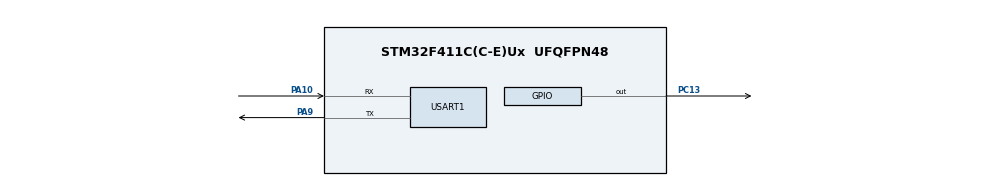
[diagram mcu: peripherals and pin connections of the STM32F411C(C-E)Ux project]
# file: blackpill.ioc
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Dma.Request0=USART1_RX
Dma.Request1=USART1_TX
Dma.USART1_RX.0.Direction=DMA_PERIPH_TO_MEMORY
Dma.USART1_RX.0.FIFOMode=DMA_FIFOMODE_DISABLE
Dma.USART1_RX.0.Instance=DMA2_Stream2
Dma.USART1_RX.0.MemDataAlignment=DMA_MDATAALIGN_BYTE
Dma.USART1_RX.0.MemInc=DMA_MINC_ENABLE
Dma.USART1_RX.0.Mode=DMA_NORMAL
Dma.USART1_RX.0.PeriphDataAlignment=DMA_PDATAALIGN_BYTE
Dma.USART1_RX.0.PeriphInc=DMA_PINC_DISABLE
Dma.USART1_RX.0.Priority=DMA_PRIORITY_LOW
Dma.USART1_TX.1.Direction=DMA_MEMORY_TO_PERIPH
Dma.USART1_TX.1.FIFOMode=DMA_FIFOMODE_DISABLE
Dma.USART1_TX.1.Instance=DMA2_Stream7
Dma.USART1_TX.1.MemDataAlignment=DMA_MDATAALIGN_BYTE
Dma.USART1_TX.1.MemInc=DMA_MINC_ENABLE
Dma.USART1_TX.1.Mode=DMA_NORMAL
Dma.USART1_TX.1.PeriphDataAlignment=DMA_PDATAALIGN_BYTE
Dma.USART1_TX.1.PeriphInc=DMA_PINC_DISABLE
Dma.USART1_TX.1.Priority=DMA_PRIORITY_LOW
Mcu.Family=STM32F4
Mcu.Name=STM32F411C(C-E)Ux
Mcu.Package=UFQFPN48
NVIC.DMA2_Stream2_IRQn=true\:0\:0\:false\:false\:false\:false\:false\:true
NVIC.PriorityGroup=NVIC_PRIORITYGROUP_4
NVIC.USART1_IRQn=true\:0\:0\:false\:false\:false\:true\:false\:true
PA10.Mode=Asynchronous
PA10.Signal=USART1_RX
PA13.Mode=Serial_Wire
PA13.Signal=SYS_JTMS-SWDIO
PA14.Mode=Serial_Wire
PA14.Signal=SYS_JTCK-SWCLK
PA9.Mode=Asynchronous
PA9.Signal=USART1_TX
PC13-ANTI_TAMP.PinState=GPIO_PIN_SET
PC13-ANTI_TAMP.Signal=GPIO_Output
PH0\ -\ OSC_IN.Mode=HSE-External-Oscillator
PH0\ -\ OSC_IN.Signal=RCC_OSC_IN
PH1\ -\ OSC_OUT.Mode=HSE-External-Oscillator
PH1\ -\ OSC_OUT.Signal=RCC_OSC_OUT
ProjectManager.HeapSize=0x200
ProjectManager.StackSize=0x400
ProjectManager.TargetToolchain=Makefile
RCC.48MHZClocksFreq_Value=50000000
RCC.AHBFreq_Value=100000000
RCC.APB1CLKDivider=RCC_HCLK_DIV2
RCC.APB1Freq_Value=50000000
RCC.APB1TimFreq_Value=100000000
RCC.APB2Freq_Value=100000000
RCC.APB2TimFreq_Value=100000000
RCC.CortexFreq_Value=100000000
RCC.HCLKFreq_Value=100000000
RCC.HSE_VALUE=25000000
RCC.HSI_VALUE=16000000
RCC.LSE_VALUE=32768
RCC.PLLM=12
RCC.PLLN=96
RCC.PLLSourceVirtual=RCC_PLLSOURCE_HSE
RCC.SYSCLKFreq_VALUE=100000000
RCC.SYSCLKSource=RCC_SYSCLKSOURCE_PLLCLK
RCC.VCOOutputFreq_Value=200000000
USART1.VirtualMode=VM_ASYNC
board=custom

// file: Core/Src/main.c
/* USER CODE BEGIN Header */
/**
  ******************************************************************************
  * @file           : main.c
  * @brief          : Main program body
  ******************************************************************************
  * @attention
  *
  * Copyright (c) 2025 STMicroelectronics.
  * All rights reserved.
  *
  * This software is licensed under terms that can be found in the LICENSE file
  * in the root directory of this software component.
  * If no LICENSE file comes with this software, it is provided AS-IS.
  *
  ******************************************************************************
  */
/* USER CODE END Header */
#include "main.h"

void SystemClock_Config(void);
static void MX_GPIO_Init(void);
static void MX_DMA_Init(void);
static void MX_USART1_UART_Init(void);

/* USER CODE BEGIN 0 */
void hal_failed_assert_handler(const char* file, const uint32_t line, const uint32_t pc);
void hal_error_handler(const uint32_t pc);
void controller_initialize_hardware_and_start_scheduler(void);
/* USER CODE END 0 */

int main(void)
{

  /* MCU Configuration--------------------------------------------------------*/

  /* Reset of all peripherals, Initializes the Flash interface and the Systick. */
  LL_APB2_GRP1_EnableClock(LL_APB2_GRP1_PERIPH_SYSCFG);
  LL_APB1_GRP1_EnableClock(LL_APB1_GRP1_PERIPH_PWR);

  /* System interrupt init*/
  NVIC_SetPriorityGrouping(NVIC_PRIORITYGROUP_4);

  /* SysTick_IRQn interrupt configuration */
  NVIC_SetPriority(SysTick_IRQn, NVIC_EncodePriority(NVIC_GetPriorityGrouping(),15, 0));

  /* Configure the system clock */
  SystemClock_Config();

  /* USER CODE BEGIN SysInit */
  SCB->SHCSR |= (SCB_SHCSR_MEMFAULTENA_Msk |
                 SCB_SHCSR_BUSFAULTENA_Msk |
                 SCB_SHCSR_USGFAULTENA_Msk);
  /* USER CODE END SysInit */

  /* Initialize all configured peripherals */
  MX_GPIO_Init();
  MX_DMA_Init();
  MX_USART1_UART_Init();
  /* USER CODE BEGIN 2 */

  controller_initialize_hardware_and_start_scheduler();

  /* USER CODE END 2 */

  /* Infinite loop */
  while (1)
  {

  }
}

void SystemClock_Config(void)
{
  LL_FLASH_SetLatency(LL_FLASH_LATENCY_3);
  while(LL_FLASH_GetLatency()!= LL_FLASH_LATENCY_3)
  {
  }
  LL_PWR_SetRegulVoltageScaling(LL_PWR_REGU_VOLTAGE_SCALE1);
  LL_RCC_HSE_Enable();

   /* Wait till HSE is ready */
  while(LL_RCC_HSE_IsReady() != 1)
  {

  }
  LL_RCC_PLL_ConfigDomain_SYS(LL_RCC_PLLSOURCE_HSE, LL_RCC_PLLM_DIV_12, 96, LL_RCC_PLLP_DIV_2);
  LL_RCC_PLL_Enable();

   /* Wait till PLL is ready */
  while(LL_RCC_PLL_IsReady() != 1)
  {

  }
  while (LL_PWR_IsActiveFlag_VOS() == 0)
  {
  }
  LL_RCC_SetAHBPrescaler(LL_RCC_SYSCLK_DIV_1);
  LL_RCC_SetAPB1Prescaler(LL_RCC_APB1_DIV_2);
  LL_RCC_SetAPB2Prescaler(LL_RCC_APB2_DIV_1);
  LL_RCC_SetSysClkSource(LL_RCC_SYS_CLKSOURCE_PLL);

   /* Wait till System clock is ready */
  while(LL_RCC_GetSysClkSource() != LL_RCC_SYS_CLKSOURCE_STATUS_PLL)
  {

  }
  LL_Init1msTick(100000000);
  LL_SetSystemCoreClock(100000000);
  LL_RCC_SetTIMPrescaler(LL_RCC_TIM_PRESCALER_TWICE);
}

static void MX_USART1_UART_Init(void)
{

  LL_USART_InitTypeDef USART_InitStruct = {0};

  LL_GPIO_InitTypeDef GPIO_InitStruct = {0};

  /* Peripheral clock enable */
  LL_APB2_GRP1_EnableClock(LL_APB2_GRP1_PERIPH_USART1);

  LL_AHB1_GRP1_EnableClock(LL_AHB1_GRP1_PERIPH_GPIOA);
  /**USART1 GPIO Configuration
  PA9   ------> USART1_TX
  PA10   ------> USART1_RX
  */
  GPIO_InitStruct.Pin = LL_GPIO_PIN_9|LL_GPIO_PIN_10;
  GPIO_InitStruct.Mode = LL_GPIO_MODE_ALTERNATE;
  GPIO_InitStruct.Speed = LL_GPIO_SPEED_FREQ_VERY_HIGH;
  GPIO_InitStruct.OutputType = LL_GPIO_OUTPUT_PUSHPULL;
  GPIO_InitStruct.Pull = LL_GPIO_PULL_NO;
  GPIO_InitStruct.Alternate = LL_GPIO_AF_7;
  LL_GPIO_Init(GPIOA, &GPIO_InitStruct);

  /* USART1 DMA Init */

  /* USART1_RX Init */
  LL_DMA_SetChannelSelection(DMA2, LL_DMA_STREAM_2, LL_DMA_CHANNEL_4);

  LL_DMA_SetDataTransferDirection(DMA2, LL_DMA_STREAM_2, LL_DMA_DIRECTION_PERIPH_TO_MEMORY);

  LL_DMA_SetStreamPriorityLevel(DMA2, LL_DMA_STREAM_2, LL_DMA_PRIORITY_LOW);

  LL_DMA_SetMode(DMA2, LL_DMA_STREAM_2, LL_DMA_MODE_NORMAL);

  LL_DMA_SetPeriphIncMode(DMA2, LL_DMA_STREAM_2, LL_DMA_PERIPH_NOINCREMENT);

  LL_DMA_SetMemoryIncMode(DMA2, LL_DMA_STREAM_2, LL_DMA_MEMORY_INCREMENT);

  LL_DMA_SetPeriphSize(DMA2, LL_DMA_STREAM_2, LL_DMA_PDATAALIGN_BYTE);

  LL_DMA_SetMemorySize(DMA2, LL_DMA_STREAM_2, LL_DMA_MDATAALIGN_BYTE);

  LL_DMA_DisableFifoMode(DMA2, LL_DMA_STREAM_2);

  /* USART1_TX Init */
  LL_DMA_SetChannelSelection(DMA2, LL_DMA_STREAM_7, LL_DMA_CHANNEL_4);

  LL_DMA_SetDataTransferDirection(DMA2, LL_DMA_STREAM_7, LL_DMA_DIRECTION_MEMORY_TO_PERIPH);

  LL_DMA_SetStreamPriorityLevel(DMA2, LL_DMA_STREAM_7, LL_DMA_PRIORITY_LOW);

  LL_DMA_SetMode(DMA2, LL_DMA_STREAM_7, LL_DMA_MODE_NORMAL);

  LL_DMA_SetPeriphIncMode(DMA2, LL_DMA_STREAM_7, LL_DMA_PERIPH_NOINCREMENT);

  LL_DMA_SetMemoryIncMode(DMA2, LL_DMA_STREAM_7, LL_DMA_MEMORY_INCREMENT);

  LL_DMA_SetPeriphSize(DMA2, LL_DMA_STREAM_7, LL_DMA_PDATAALIGN_BYTE);

  LL_DMA_SetMemorySize(DMA2, LL_DMA_STREAM_7, LL_DMA_MDATAALIGN_BYTE);

  LL_DMA_DisableFifoMode(DMA2, LL_DMA_STREAM_7);

  /* USART1 interrupt Init */
  NVIC_SetPriority(USART1_IRQn, NVIC_EncodePriority(NVIC_GetPriorityGrouping(),5, 0));
  NVIC_EnableIRQ(USART1_IRQn);

  USART_InitStruct.BaudRate = 115200;
  USART_InitStruct.DataWidth = LL_USART_DATAWIDTH_8B;
  USART_InitStruct.StopBits = LL_USART_STOPBITS_1;
  USART_InitStruct.Parity = LL_USART_PARITY_NONE;
  USART_InitStruct.TransferDirection = LL_USART_DIRECTION_TX_RX;
  USART_InitStruct.HardwareFlowControl = LL_USART_HWCONTROL_NONE;
  USART_InitStruct.OverSampling = LL_USART_OVERSAMPLING_16;
  LL_USART_Init(USART1, &USART_InitStruct);
  LL_USART_ConfigAsyncMode(USART1);
  LL_USART_Enable(USART1);

}

static void MX_DMA_Init(void)
{

  /* Init with LL driver */
  /* DMA controller clock enable */
  LL_AHB1_GRP1_EnableClock(LL_AHB1_GRP1_PERIPH_DMA2);

  /* DMA interrupt init */
  /* DMA2_Stream2_IRQn interrupt configuration */
  NVIC_SetPriority(DMA2_Stream2_IRQn, NVIC_EncodePriority(NVIC_GetPriorityGrouping(),5, 0));
  NVIC_EnableIRQ(DMA2_Stream2_IRQn);

}

static void MX_GPIO_Init(void)
{
  LL_GPIO_InitTypeDef GPIO_InitStruct = {0};

  /* GPIO Ports Clock Enable */
  LL_AHB1_GRP1_EnableClock(LL_AHB1_GRP1_PERIPH_GPIOC);
  LL_AHB1_GRP1_EnableClock(LL_AHB1_GRP1_PERIPH_GPIOH);
  LL_AHB1_GRP1_EnableClock(LL_AHB1_GRP1_PERIPH_GPIOA);

  /**/
  LL_GPIO_SetOutputPin(GPIOC, LL_GPIO_PIN_13);

  /**/
  GPIO_InitStruct.Pin = LL_GPIO_PIN_13;
  GPIO_InitStruct.Mode = LL_GPIO_MODE_OUTPUT;
  GPIO_InitStruct.Speed = LL_GPIO_SPEED_FREQ_LOW;
  GPIO_InitStruct.OutputType = LL_GPIO_OUTPUT_PUSHPULL;
  GPIO_InitStruct.Pull = LL_GPIO_PULL_NO;
  LL_GPIO_Init(GPIOC, &GPIO_InitStruct);

}

void Error_Handler(void)
{
  /* USER CODE BEGIN Error_Handler_Debug */
  /* User can add his own implementation to report the HAL error return state */
  const void* pc = __builtin_return_address(0);
  hal_error_handler((uint32_t)pc);
  /* USER CODE END Error_Handler_Debug */
}

#ifdef  USE_FULL_ASSERT
/**
  * @brief  Reports the name of the source file and the source line number
  *         where the assert_param error has occurred.
  * @param  file: pointer to the source file name
  * @param  line: assert_param error line source number
  * @retval None
  */
void assert_failed(uint8_t *file, uint32_t line)
{
  /* USER CODE BEGIN 6 */
  /* User can add his own implementation to report the file name and line number,
     ex: printf("Wrong parameters value: file %s on line %d\r\n", file, line) */
  const void* pc = __builtin_return_address(0);
  hal_failed_assert_handler((const char*)file, line, (uint32_t)pc);
  /* USER CODE END 6 */
}
#endif /* USE_FULL_ASSERT */
